VERSION "blobly-1.0"

NS_ :

	BS_:
	CM_
	BA_DEF_
	BA_
	CM_ SG_

BS_:

BU_: SUT Tester BodyECU ChassisECU BatteryECU

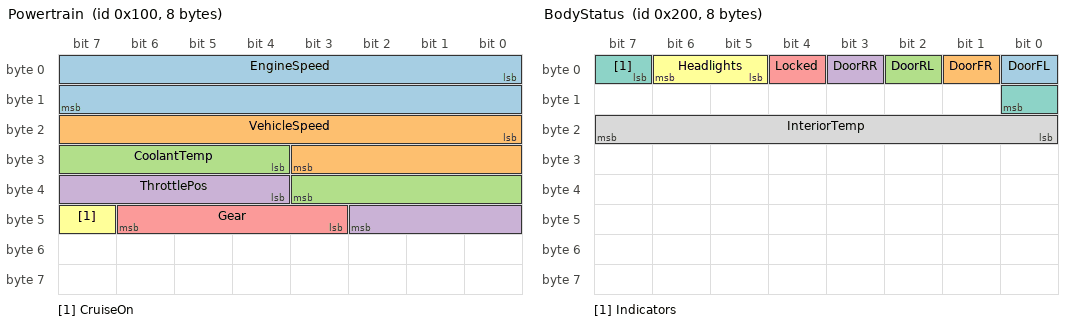
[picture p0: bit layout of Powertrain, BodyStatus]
BO_ 256 Powertrain: 8 SUT
 SG_ EngineSpeed : 0|16@1+ (0.25,0) [0|16383.75] "rpm" Tester
 SG_ VehicleSpeed : 16|12@1+ (0.1,0) [0|409.5] "km/h" Tester
 SG_ CoolantTemp : 28|8@1+ (1,-40) [-40|215] "degC" Tester
 SG_ ThrottlePos : 36|7@1+ (1,0) [0|127] "%" Tester
 SG_ Gear : 43|4@1+ (1,0) [0|15] "" Tester
 SG_ CruiseOn : 47|1@1+ (1,0) [0|1] "" Tester

BO_ 272 LampFrame: 3 SUT
 SG_ WarnLamp : 0|1@1+ (1,0) [0|1] "" Tester

BO_ 304 SecureFrame: 8 SUT
 SG_ SecureStatus : 0|8@1+ (1,0) [0|255] "" Tester

BO_ 1792 Heartbeat: 1 SUT
 SG_ Counter : 0|8@1+ (1,0) [0|255] "" Tester

BO_ 257 Request: 8 Tester
 SG_ ReqCode : 0|8@1+ (1,0) [0|255] "" SUT

BO_ 258 Response: 8 SUT
 SG_ RespCode : 0|8@1+ (1,0) [0|255] "" Tester

BO_ 512 BodyStatus: 8 BodyECU
 SG_ DoorFL : 0|1@1+ (1,0) [0|1] "" Tester
 SG_ DoorFR : 1|1@1+ (1,0) [0|1] "" Tester
 SG_ DoorRL : 2|1@1+ (1,0) [0|1] "" Tester
 SG_ DoorRR : 3|1@1+ (1,0) [0|1] "" Tester
 SG_ Locked : 4|1@1+ (1,0) [0|1] "" Tester
 SG_ Headlights : 5|2@1+ (1,0) [0|3] "" Tester
 SG_ Indicators : 7|2@1+ (1,0) [0|3] "" Tester
 SG_ InteriorTemp : 16|8@1+ (0.5,-40) [-40|87.5] "degC" Tester

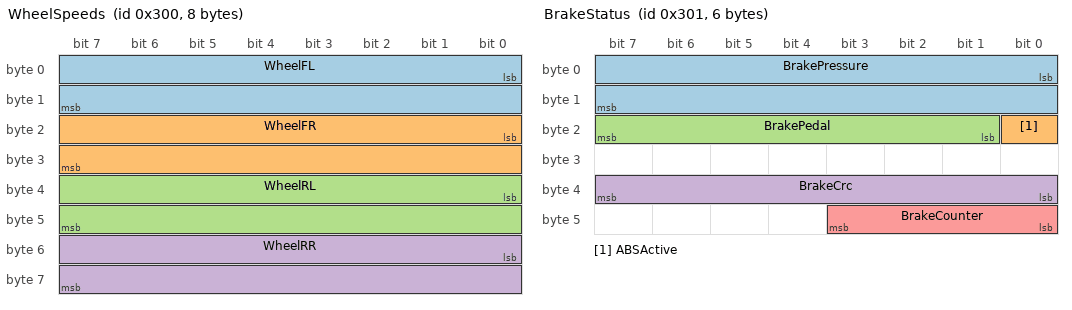
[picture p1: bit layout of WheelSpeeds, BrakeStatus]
BO_ 768 WheelSpeeds: 8 ChassisECU
 SG_ WheelFL : 0|16@1+ (0.01,0) [0|655.35] "km/h" Tester
 SG_ WheelFR : 16|16@1+ (0.01,0) [0|655.35] "km/h" Tester
 SG_ WheelRL : 32|16@1+ (0.01,0) [0|655.35] "km/h" Tester
 SG_ WheelRR : 48|16@1+ (0.01,0) [0|655.35] "km/h" Tester

BO_ 769 BrakeStatus: 6 ChassisECU
 SG_ BrakePressure : 0|16@1+ (0.1,0) [0|6553.5] "kPa" Tester
 SG_ ABSActive : 16|1@1+ (1,0) [0|1] "" Tester
 SG_ BrakePedal : 17|7@1+ (1,0) [0|100] "%" Tester
 SG_ BrakeCrc : 32|8@1+ (1,0) [0|255] "" Tester
 SG_ BrakeCounter : 40|4@1+ (1,0) [0|15] "" Tester

BO_ 770 Ignition: 1 Tester
 SG_ IgnitionOn : 0|1@1+ (1,0) [0|1] "" SUT

BO_ 305 BrakeReport: 3 SUT
 SG_ BrakeRxStatus : 0|8@1+ (1,0) [0|255] "" Tester
 SG_ BrakeLost : 8|16@1+ (1,0) [0|65535] "" Tester

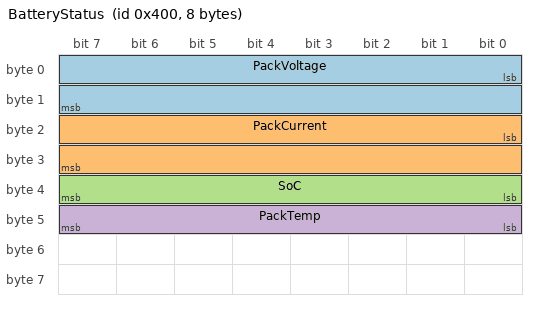
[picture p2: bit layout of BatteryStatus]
BO_ 1024 BatteryStatus: 8 BatteryECU
 SG_ PackVoltage : 0|16@1+ (0.01,0) [0|655.35] "V" Tester
 SG_ PackCurrent : 16|16@1- (0.1,0) [-3276.8|3276.7] "A" Tester
 SG_ SoC : 32|8@1+ (0.5,0) [0|100] "%" Tester
 SG_ PackTemp : 40|8@1+ (1,-40) [-40|215] "degC" Tester

CM_ SG_ 256 EngineSpeed "Crankshaft rotational speed";
CM_ SG_ 256 VehicleSpeed "Road speed of the vehicle";
CM_ SG_ 256 CoolantTemp "Engine coolant temperature";
CM_ SG_ 256 ThrottlePos "Accelerator pedal / throttle position";
CM_ SG_ 256 Gear "Currently engaged gear";
CM_ SG_ 256 CruiseOn "Cruise control active flag";
CM_ SG_ 1792 Counter "Rolling alive counter";

VAL_ 256 Gear 0 "Neutral" 1 "First" 2 "Second" 3 "Third" 4 "Fourth" 5 "Fifth" 6 "Sixth" ;
VAL_ 256 CruiseOn 0 "Off" 1 "On" ;
VAL_ 512 Headlights 0 "Off" 1 "Low" 2 "High" 3 "Auto" ;
VAL_ 512 Indicators 0 "Off" 1 "Left" 2 "Right" 3 "Hazard" ;
VAL_ 769 ABSActive 0 "Inactive" 1 "Active" ;

BA_DEF_ BO_ "GenMsgCycleTime" INT 0 65535;
BA_DEF_ BO_ "E2ECounterSignal" STRING;
BA_DEF_ BO_ "E2ECrcSignal" STRING;
BA_DEF_ BO_ "E2EProfile" STRING;
BA_DEF_ BO_ "E2EDataId" INT 0 65535;
BA_DEF_ BO_ "E2ETimeout" INT 0 65535;
BA_ "GenMsgCycleTime" BO_ 256 100;
BA_ "GenMsgCycleTime" BO_ 1792 100;
BA_ "GenMsgCycleTime" BO_ 512 200;
BA_ "GenMsgCycleTime" BO_ 768 20;
BA_ "GenMsgCycleTime" BO_ 769 50;
BA_ "GenMsgCycleTime" BO_ 1024 500;
BA_ "E2ECounterSignal" BO_ 769 "BrakeCounter";
BA_ "E2ECrcSignal" BO_ 769 "BrakeCrc";
BA_ "E2EProfile" BO_ 769 "P01";
BA_ "E2EDataId" BO_ 769 68;
BA_ "E2ETimeout" BO_ 769 300;
